AUTOSAR XML (schema 314)
package /ComponentType
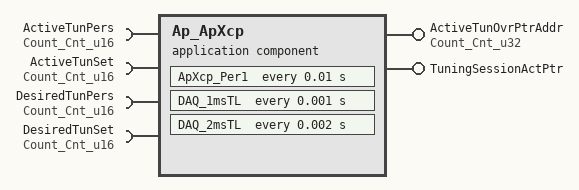
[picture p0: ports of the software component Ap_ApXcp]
  application software component type Ap_ApXcp
    provide port ActiveTunOvrPtrAddr: unqueued-sender-com-spec{data-element=Cnt_u32, can-invalidate=false, init-value=D_ZERO_CNT_U32}, provided-interface=Count_Cnt_u32
    provide port TuningSessionActPtr: unqueued-sender-com-spec{data-element=Cnt_u8, can-invalidate=false, init-value=C_INIT_TUNINGSESSIONADDRPTRENUM}, provided-interface=TuningSessionActPtr
    4 x require port, all with unqueued-receiver-com-spec{data-element=Cnt_u16, init-value=D_ZERO_CNT_U16}, required-interface=Count_Cnt_u16:
      ActiveTunPers
      ActiveTunSet
      DesiredTunPers
      DesiredTunSet
  internal behavior Ap_ApXcp_InternalBehavior: component=Ap_ApXcp
    timing event TMT_ApXcp_Per1: start-on-event=ApXcp_Per1, period=0.01
    timing event TMT_DAQ_1msTL: start-on-event=DAQ_1msTL, period=0.001
    timing event TMT_DAQ_2msTL: start-on-event=DAQ_2msTL, period=0.002
    port-api-options:
      enable-take-address=false, indirect-api=false, port=ActiveTunOvrPtrAddr
      enable-take-address=false, indirect-api=false, port=ActiveTunPers
      enable-take-address=false, indirect-api=false, port=ActiveTunSet
      enable-take-address=false, indirect-api=false, port=DesiredTunPers
      enable-take-address=false, indirect-api=false, port=DesiredTunSet
      enable-take-address=false, indirect-api=false, port=TuningSessionActPtr
    runnable ApXcp_Per1
      4 x data read access:
        READ_ActiveTunPers_Cnt_u16: data-element=ActiveTunPers.Cnt_u16
        READ_ActiveTunSet_Cnt_u16: data-element=ActiveTunSet.Cnt_u16
        READ_DesiredTunPers_Cnt_u16: data-element=DesiredTunPers.Cnt_u16
        READ_DesiredTunSet_Cnt_u16: data-element=DesiredTunSet.Cnt_u16
      data write access WRITE_ActiveTunOvrPtrAddr_Cnt_u32: data-element=ActiveTunOvrPtrAddr.Cnt_u32
      data write access WRITE_TuningSessionActPtr_Cnt_u8: data-element=TuningSessionActPtr.Cnt_u8
    runnable DAQ_1msTL
    runnable DAQ_2msTL
  swc implementation Ap_ApXcp_Implementation: behavior=Ap_ApXcp_InternalBehavior
    code-descriptors:
      code Code: type=SRC
